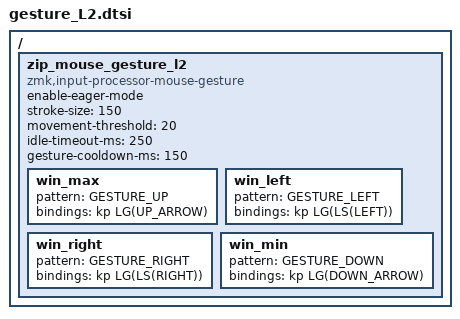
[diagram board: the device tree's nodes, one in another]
/*
 * Layer 10 (旧Layer 2) Mouse Gestures
 *
 * Bindings:
 */

/ {
    zip_mouse_gesture_l2: zip_mouse_gesture_l2 {
        compatible = "zmk,input-processor-mouse-gesture";
        #input-processor-cells = <0>;
        enable-eager-mode;

        stroke-size = <150>;
        movement-threshold = <20>;
        idle-timeout-ms = <250>;
        gesture-cooldown-ms = <150>;

        win_max    { pattern = <GESTURE_UP>;    bindings = <&kp LG(UP_ARROW)>; };
        win_left { pattern = <GESTURE_LEFT>;  bindings = <&kp LG(LS(LEFT))>; };
        win_right { pattern = <GESTURE_RIGHT>; bindings = <&kp LG(LS(RIGHT))>; };
win_min    { pattern = <GESTURE_DOWN>;  bindings = <&kp LG(DOWN_ARROW)>; };
    };
};
